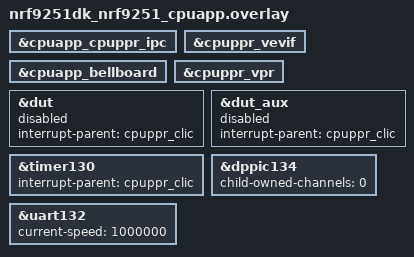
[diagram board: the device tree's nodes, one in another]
/*
 * Copyright (c) 2026 Nordic Semiconductor ASA
 *
 * SPDX-License-Identifier: LicenseRef-Nordic-5-Clause
 */

#include "../../../boards/nrf9251dk_nrf9251_cpuapp.overlay"

&cpuapp_cpuppr_ipc {
	status = "okay";
};

&cpuppr_vevif {
	status = "okay";
};

&cpuapp_bellboard {
	status = "okay";
};

&cpuppr_vpr {
	status = "okay";
};

&dut {
	status = "reserved";
	interrupt-parent = <&cpuppr_clic>;
};

&dut_aux {
	status = "reserved";
	interrupt-parent = <&cpuppr_clic>;
};

&timer130 {
	interrupt-parent = <&cpuppr_clic>;
};

&dppic134 {
	child-owned-channels = <0>;
};

&uart132 {
	current-speed = <1000000>;
};
